# ATSAMA5D27CLD2G register map
Vendor: Microchip Technology; Series: SAMA5D2; File version: 0
Registers are 32-bit, read-write, reset 0x0 unless marked. A register's access mark holds for its fields unless they carry their own. Offsets are from the block's base; [hi:lo] are bit positions; {n}, {i} and the like mark numbered series.

## TWIHS0 — Two-wire Interface High Speed
Base 0xF8028000; register names take the prefix TWIHS_
Same registers: TWIHS1 0xFC028000
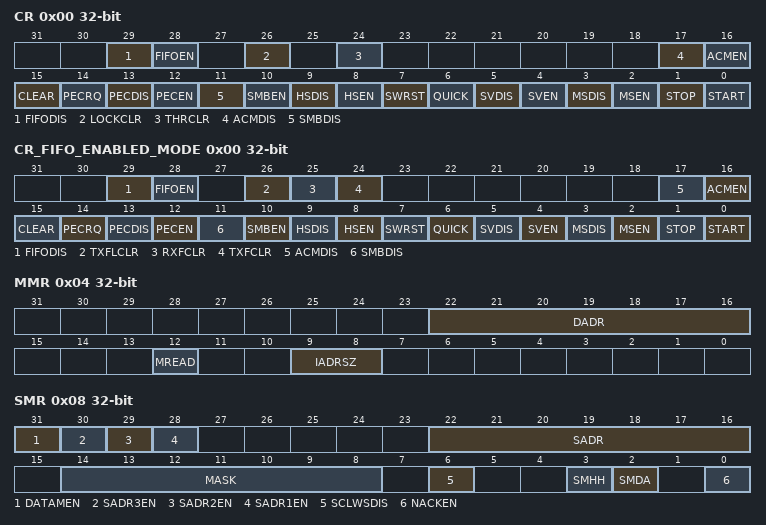
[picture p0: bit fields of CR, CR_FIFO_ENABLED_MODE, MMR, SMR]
0x00 CR wo — Control Register
  [29] FIFODIS — FIFO Disable
  [28] FIFOEN — FIFO Enable
  [26] LOCKCLR — Lock Clear
  [24] THRCLR — Transmit Holding Register Clear
  [17] ACMDIS — Alternative Command Mode Disable
  [16] ACMEN — Alternative Command Mode Enable
  [15] CLEAR — Bus CLEAR Command
  [14] PECRQ — PEC Request
  [13] PECDIS — Packet Error Checking Disable
  [12] PECEN — Packet Error Checking Enable
  [11] SMBDIS — SMBus Mode Disabled
  [10] SMBEN — SMBus Mode Enabled
  [9] HSDIS — TWIHS High-Speed Mode Disabled
  [8] HSEN — TWIHS High-Speed Mode Enabled
  [7] SWRST — Software Reset
  [6] QUICK — SMBus Quick Command
  [5] SVDIS — TWIHS Slave Mode Disabled
  [4] SVEN — TWIHS Slave Mode Enabled
  [3] MSDIS — TWIHS Master Mode Disabled
  [2] MSEN — TWIHS Master Mode Enabled
  [1] STOP — Send a STOP Condition
  [0] START — Send a START Condition
0x00 CR_FIFO_ENABLED_MODE wo (alternate view of CR) — Control Register
  [29] FIFODIS — FIFO Disable
  [28] FIFOEN — FIFO Enable
  [26] TXFLCLR — Transmit FIFO Lock CLEAR
  [25] RXFCLR — Receive FIFO Clear
  [24] TXFCLR — Transmit FIFO Clear
  [17] ACMDIS — Alternative Command Mode Disable
  [16] ACMEN — Alternative Command Mode Enable
  [15] CLEAR — Bus CLEAR Command
  [14] PECRQ — PEC Request
  [13] PECDIS — Packet Error Checking Disable
  [12] PECEN — Packet Error Checking Enable
  [11] SMBDIS — SMBus Mode Disabled
  [10] SMBEN — SMBus Mode Enabled
  [9] HSDIS — TWIHS High-Speed Mode Disabled
  [8] HSEN — TWIHS High-Speed Mode Enabled
  [7] SWRST — Software Reset
  [6] QUICK — SMBus Quick Command
  [5] SVDIS — TWIHS Slave Mode Disabled
  [4] SVEN — TWIHS Slave Mode Enabled
  [3] MSDIS — TWIHS Master Mode Disabled
  [2] MSEN — TWIHS Master Mode Enabled
  [1] STOP — Send a STOP Condition
  [0] START — Send a START Condition
0x04 MMR — Master Mode Register
  [22:16] DADR — Device Address
  [12] MREAD — Master Read Direction
  [9:8] IADRSZ — Internal Device Address Size
    0=NONE (No internal device address); 1=_1_BYTE (One-byte internal device address); 2=_2_BYTE (Two-byte internal device address); 3=_3_BYTE (Three-byte internal device address)
0x08 SMR — Slave Mode Register
  [31] DATAMEN — Data Matching Enable
  [30] SADR3EN — Slave Address 3 Enable
  [29] SADR2EN — Slave Address 2 Enable
  [28] SADR1EN — Slave Address 1 Enable
  [22:16] SADR — Slave Address
  [14:8] MASK — Slave Address Mask
  [6] SCLWSDIS — Clock Wait State Disable
  [3] SMHH — SMBus Host Header
  [2] SMDA — SMBus Default Address
  [0] NACKEN — Slave Receiver Data Phase NACK enable
0x0C IADR — Internal Address Register
  [23:0] IADR — Internal Address
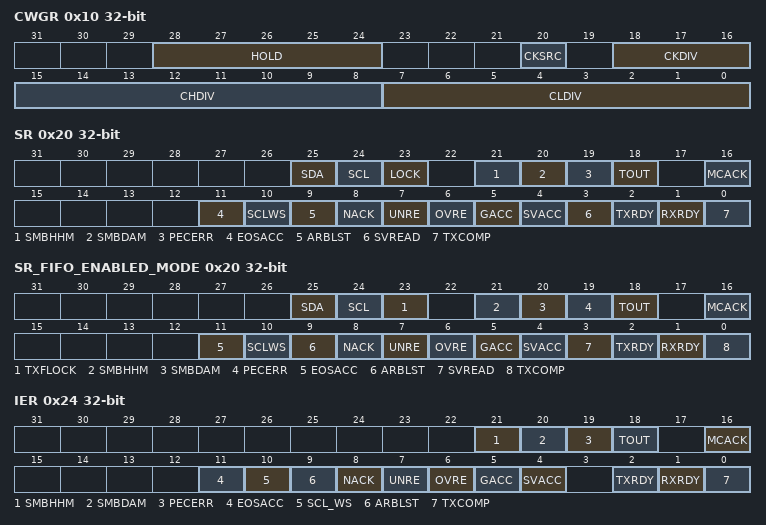
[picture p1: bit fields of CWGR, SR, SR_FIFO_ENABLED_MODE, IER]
0x10 CWGR — Clock Waveform Generator Register
  [28:24] HOLD — TWD Hold Time Versus TWCK Falling
  [20] CKSRC — Transfer Rate Clock Source
    0=PERIPH_CK (Peripheral clock is used to generate the TWIHS baud rate.); 1=GCLK (GCLK is used to generate the TWIHS baud rate.)
  [18:16] CKDIV — Clock Divider
  [15:8] CHDIV — Clock High Divider
  [7:0] CLDIV — Clock Low Divider
0x20 SR ro — Status Register
  [25] SDA — SDA Line Value
  [24] SCL — SCL Line Value
  [23] LOCK — TWIHS Lock due to Frame Errors (cleared by writing a one to bit LOCKCLR in TWIHS_CR)
  [21] SMBHHM — SMBus Host Header Address Match (cleared on read)
  [20] SMBDAM — SMBus Default Address Match (cleared on read)
  [19] PECERR — PEC Error (cleared on read)
  [18] TOUT — Timeout Error (cleared on read)
  [16] MCACK — Master Code Acknowledge (cleared on read)
  [11] EOSACC — End Of Slave Access (cleared on read)
  [10] SCLWS — Clock Wait State
  [9] ARBLST — Arbitration Lost (cleared on read)
  [8] NACK — Not Acknowledged (cleared on read)
  [7] UNRE — Underrun Error (cleared on read)
  [6] OVRE — Overrun Error (cleared on read)
  [5] GACC — General Call Access (cleared on read)
  [4] SVACC — Slave Access
  [3] SVREAD — Slave Read
  [2] TXRDY — Transmit Holding Register Ready (cleared by writing TWIHS_THR)
  [1] RXRDY — Receive Holding Register Ready (cleared by reading TWIHS_RHR)
  [0] TXCOMP — Transmission Completed (cleared by writing TWIHS_THR)
0x20 SR_FIFO_ENABLED_MODE ro (alternate view of SR) — Status Register
  [25] SDA — SDA Line Value
  [24] SCL — SCL Line Value
  [23] TXFLOCK — Transmit FIFO Lock
  [21] SMBHHM — SMBus Host Header Address Match (cleared on read)
  [20] SMBDAM — SMBus Default Address Match (cleared on read)
  [19] PECERR — PEC Error (cleared on read)
  [18] TOUT — Timeout Error (cleared on read)
  [16] MCACK — Master Code Acknowledge (cleared on read)
  [11] EOSACC — End Of Slave Access (cleared on read)
  [10] SCLWS — Clock Wait State
  [9] ARBLST — Arbitration Lost (cleared on read)
  [8] NACK — Not Acknowledged (cleared on read)
  [7] UNRE — Underrun Error (cleared on read)
  [6] OVRE — Overrun Error (cleared on read)
  [5] GACC — General Call Access (cleared on read)
  [4] SVACC — Slave Access
  [3] SVREAD — Slave Read
  [2] TXRDY — Transmit Holding Register Ready (cleared by writing TWIHS_THR)
  [1] RXRDY — Receive Holding Register Ready (cleared by reading TWIHS_RHR)
  [0] TXCOMP — Transmission Completed (cleared by writing TWIHS_THR)
0x24 IER wo — Interrupt Enable Register
  [21] SMBHHM — SMBus Host Header Address Match Interrupt Enable
  [20] SMBDAM — SMBus Default Address Match Interrupt Enable
  [19] PECERR — PEC Error Interrupt Enable
  [18] TOUT — Timeout Error Interrupt Enable
  [16] MCACK — Master Code Acknowledge Interrupt Enable
  [11] EOSACC — End Of Slave Access Interrupt Enable
  [10] SCL_WS — Clock Wait State Interrupt Enable
  [9] ARBLST — Arbitration Lost Interrupt Enable
  [8] NACK — Not Acknowledge Interrupt Enable
  [7] UNRE — Underrun Error Interrupt Enable
  [6] OVRE — Overrun Error Interrupt Enable
  [5] GACC — General Call Access Interrupt Enable
  [4] SVACC — Slave Access Interrupt Enable
  [2] TXRDY — Transmit Holding Register Ready Interrupt Enable
  [1] RXRDY — Receive Holding Register Ready Interrupt Enable
  [0] TXCOMP — Transmission Completed Interrupt Enable
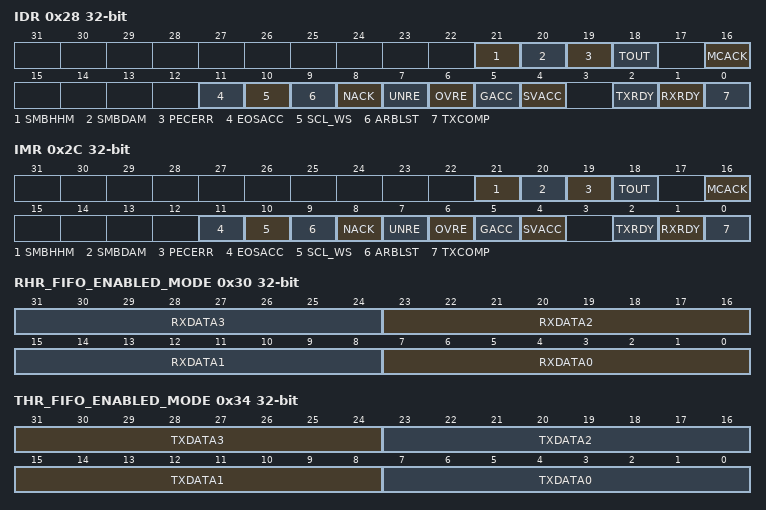
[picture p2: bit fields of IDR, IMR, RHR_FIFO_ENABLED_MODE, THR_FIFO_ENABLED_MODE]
0x28 IDR wo — Interrupt Disable Register
  [21] SMBHHM — SMBus Host Header Address Match Interrupt Disable
  [20] SMBDAM — SMBus Default Address Match Interrupt Disable
  [19] PECERR — PEC Error Interrupt Disable
  [18] TOUT — Timeout Error Interrupt Disable
  [16] MCACK — Master Code Acknowledge Interrupt Disable
  [11] EOSACC — End Of Slave Access Interrupt Disable
  [10] SCL_WS — Clock Wait State Interrupt Disable
  [9] ARBLST — Arbitration Lost Interrupt Disable
  [8] NACK — Not Acknowledge Interrupt Disable
  [7] UNRE — Underrun Error Interrupt Disable
  [6] OVRE — Overrun Error Interrupt Disable
  [5] GACC — General Call Access Interrupt Disable
  [4] SVACC — Slave Access Interrupt Disable
  [2] TXRDY — Transmit Holding Register Ready Interrupt Disable
  [1] RXRDY — Receive Holding Register Ready Interrupt Disable
  [0] TXCOMP — Transmission Completed Interrupt Disable
0x2C IMR ro — Interrupt Mask Register
  [21] SMBHHM — SMBus Host Header Address Match Interrupt Mask
  [20] SMBDAM — SMBus Default Address Match Interrupt Mask
  [19] PECERR — PEC Error Interrupt Mask
  [18] TOUT — Timeout Error Interrupt Mask
  [16] MCACK — Master Code Acknowledge Interrupt Mask
  [11] EOSACC — End Of Slave Access Interrupt Mask
  [10] SCL_WS — Clock Wait State Interrupt Mask
  [9] ARBLST — Arbitration Lost Interrupt Mask
  [8] NACK — Not Acknowledge Interrupt Mask
  [7] UNRE — Underrun Error Interrupt Mask
  [6] OVRE — Overrun Error Interrupt Mask
  [5] GACC — General Call Access Interrupt Mask
  [4] SVACC — Slave Access Interrupt Mask
  [2] TXRDY — Transmit Holding Register Ready Interrupt Mask
  [1] RXRDY — Receive Holding Register Ready Interrupt Mask
  [0] TXCOMP — Transmission Completed Interrupt Mask
0x30 RHR ro — Receive Holding Register
  [7:0] RXDATA — Master or Slave Receive Holding Data
0x30 RHR_FIFO_ENABLED_MODE ro (alternate view of RHR) — Receive Holding Register
  [8n+7:8n] RXDATA{n} (n=0..3) — Master or Slave Receive Holding Data {n}
0x34 THR wo — Transmit Holding Register
  [7:0] TXDATA — Master or Slave Transmit Holding Data
0x34 THR_FIFO_ENABLED_MODE wo (alternate view of THR) — Transmit Holding Register
  [31:24] TXDATA3 — Master or Slave Transmit Holding Data 3
  [23:16] TXDATA2 — Master or Slave Transmit Holding Data 2
  [15:8] TXDATA1 — Master or Slave Transmit Holding Data 1
  [7:0] TXDATA0 — Master or Slave Transmit Holding Data 02
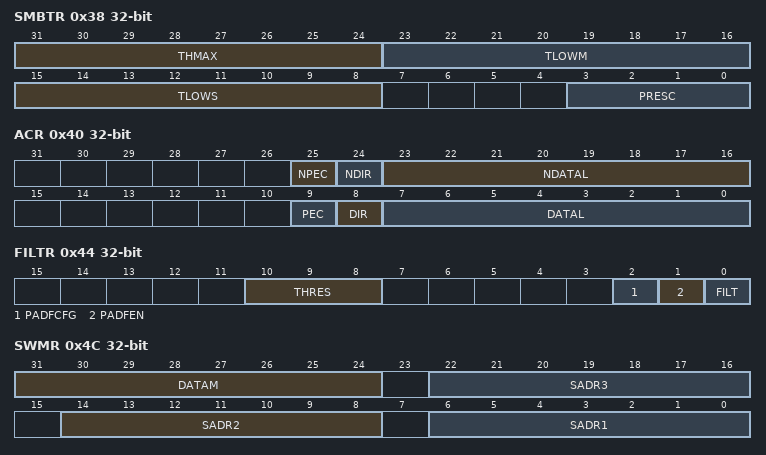
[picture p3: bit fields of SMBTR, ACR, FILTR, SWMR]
0x38 SMBTR — SMBus Timing Register
  [31:24] THMAX — Clock High Maximum Cycles
  [23:16] TLOWM — Master Clock Stretch Maximum Cycles
  [15:8] TLOWS — Slave Clock Stretch Maximum Cycles
  [3:0] PRESC — SMBus Clock Prescaler
0x40 ACR — Alternative Command Register
  [25] NPEC — Next PEC Request (SMBus Mode only)
  [24] NDIR — Next Transfer Direction
  [23:16] NDATAL — Next Data Length
  [9] PEC — PEC Request (SMBus Mode only)
  [8] DIR — Transfer Direction
  [7:0] DATAL — Data Length
0x44 FILTR — Filter Register
  [10:8] THRES — Digital Filter Threshold
  [2] PADFCFG — PAD Filter Config
  [1] PADFEN — PAD Filter Enable
  [0] FILT — RX Digital Filter
0x4C SWMR — SleepWalking Matching Register
  [31:24] DATAM — Data Match
  [22:16] SADR3 — Slave Address 3
  [14:8] SADR2 — Slave Address 2
  [6:0] SADR1 — Slave Address 1
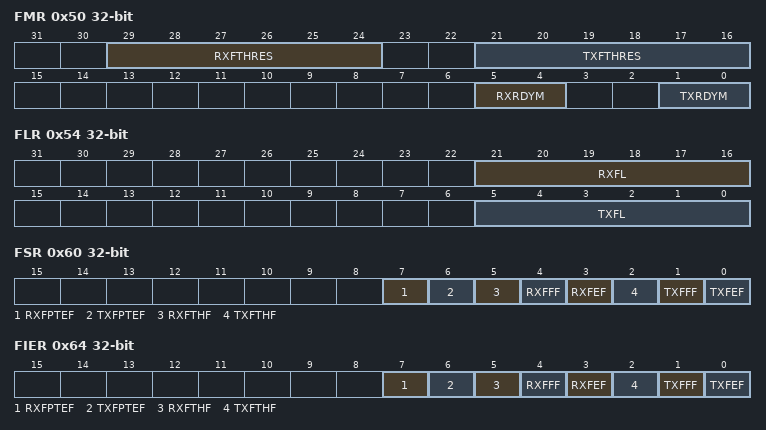
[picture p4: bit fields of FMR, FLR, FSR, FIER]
0x50 FMR — FIFO Mode Register
  [29:24] RXFTHRES — Receive FIFO Threshold
  [21:16] TXFTHRES — Transmit FIFO Threshold
  [5:4] RXRDYM — Receiver Ready Mode
    0=ONE_DATA (RXRDY will be at level '1' when at least one unread data is in the Receive FIFO); 1=TWO_DATA (RXRDY will be at level '1' when at least two unread data are in the Receive FIFO); 2=FOUR_DATA (RXRDY will be at level '1' when at least four unread data are in the Receive FIFO)
  [1:0] TXRDYM — Transmitter Ready Mode
    0=ONE_DATA (TXRDY will be at level '1' when at least one data can be written in the Transmit FIFO); 1=TWO_DATA (TXRDY will be at level '1' when at least two data can be written in the Transmit FIFO); 2=FOUR_DATA (TXRDY will be at level '1' when at least four data can be written in the Transmit FIFO)
0x54 FLR ro — FIFO Level Register
  [21:16] RXFL — Receive FIFO Level
  [5:0] TXFL — Transmit FIFO Level
0x60 FSR ro — FIFO Status Register
  [7] RXFPTEF — Receive FIFO Pointer Error Flag
  [6] TXFPTEF — Transmit FIFO Pointer Error Flag
  [5] RXFTHF — Receive FIFO Threshold Flag
  [4] RXFFF — Receive FIFO Full Flag
  [3] RXFEF — Receive FIFO Empty Flag
  [2] TXFTHF — Transmit FIFO Threshold Flag (cleared on read)
  [1] TXFFF — Transmit FIFO Full Flag (cleared on read)
  [0] TXFEF — Transmit FIFO Empty Flag (cleared on read)
0x64 FIER wo — FIFO Interrupt Enable Register
  [7] RXFPTEF — RXFPTEF Interrupt Enable
  [6] TXFPTEF — TXFPTEF Interrupt Enable
  [5] RXFTHF — RXFTHF Interrupt Enable
  [4] RXFFF — RXFFF Interrupt Enable
  [3] RXFEF — RXFEF Interrupt Enable
  [2] TXFTHF — TXFTHF Interrupt Enable
  [1] TXFFF — TXFFF Interrupt Enable
  [0] TXFEF — TXFEF Interrupt Enable
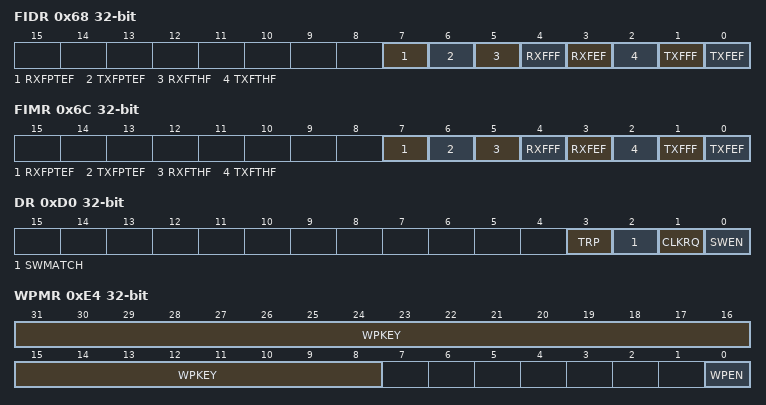
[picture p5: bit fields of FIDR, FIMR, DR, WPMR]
0x68 FIDR wo — FIFO Interrupt Disable Register
  [7] RXFPTEF — RXFPTEF Interrupt Disable
  [6] TXFPTEF — TXFPTEF Interrupt Disable
  [5] RXFTHF — RXFTHF Interrupt Disable
  [4] RXFFF — RXFFF Interrupt Disable
  [3] RXFEF — RXFEF Interrupt Disable
  [2] TXFTHF — TXFTHF Interrupt Disable
  [1] TXFFF — TXFFF Interrupt Disable
  [0] TXFEF — TXFEF Interrupt Disable
0x6C FIMR ro — FIFO Interrupt Mask Register
  [7] RXFPTEF — RXFPTEF Interrupt Mask
  [6] TXFPTEF — TXFPTEF Interrupt Mask
  [5] RXFTHF — RXFTHF Interrupt Mask
  [4] RXFFF — RXFFF Interrupt Mask
  [3] RXFEF — RXFEF Interrupt Mask
  [2] TXFTHF — TXFTHF Interrupt Mask
  [1] TXFFF — TXFFF Interrupt Mask
  [0] TXFEF — TXFEF Interrupt Mask
0xD0 DR ro — Debug Register
  [3] TRP — Transfer Pending
  [2] SWMATCH — SleepWalking Match
  [1] CLKRQ — Clock Request
  [0] SWEN — SleepWalking Enable
0xE4 WPMR — Write Protection Mode Register
  [31:8] WPKEY — Write Protection Key
    0x545749=PASSWD (Writing any other value in this field aborts the write operation of the WPEN bit.Always reads as 0)
  [0] WPEN — Write Protection Enable
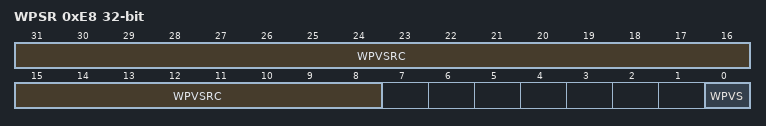
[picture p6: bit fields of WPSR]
0xE8 WPSR ro — Write Protection Status Register
  [31:8] WPVSRC — Write Protection Violation Source
  [0] WPVS — Write Protection Violation Status

## Notices in the file
Copyright (c) 2022 Microchip Technology Inc.
SPDX-License-Identifier: Apache-2.0
Licensed under the Apache License, Version 2.0 (the "License");
you may not use this file except in compliance with the License.
You may obtain a copy of the License at
http://www.apache.org/licenses/LICENSE-2.0
Unless required by applicable law or agreed to in writing, software
distributed under the License is distributed on an "AS IS" BASIS,
WITHOUT WARRANTIES OR CONDITIONS OF ANY KIND, either express or implied.
See the License for the specific language governing permissions and
limitations under the License.
